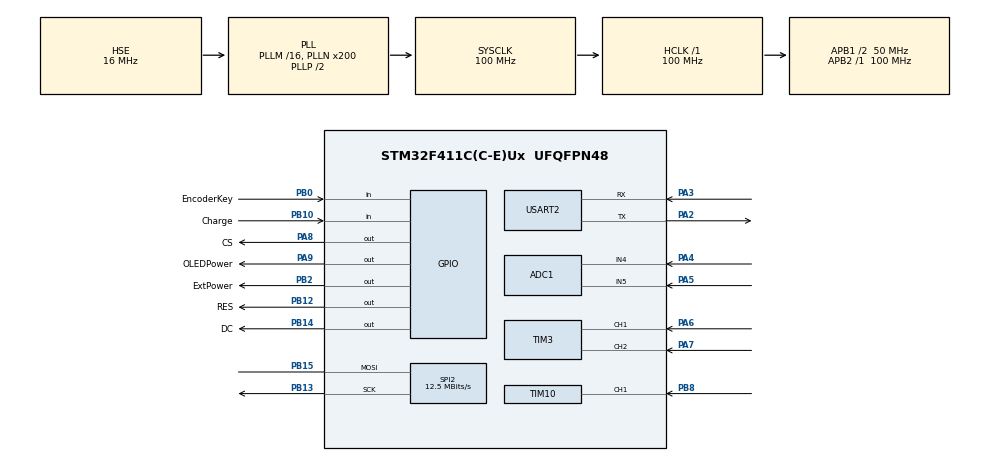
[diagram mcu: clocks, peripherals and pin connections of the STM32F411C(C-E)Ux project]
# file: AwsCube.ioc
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ADC1.Channel-0\#ChannelRegularConversion=ADC_CHANNEL_4
ADC1.NbrOfConversionFlag=1
ADC1.Rank-0\#ChannelRegularConversion=1
ADC1.SamplingTime-0\#ChannelRegularConversion=ADC_SAMPLETIME_3CYCLES
ADC1.master=1
Dma.Request0=SPI2_TX
Dma.Request1=USART2_RX
Dma.SPI2_TX.0.Direction=DMA_MEMORY_TO_PERIPH
Dma.SPI2_TX.0.FIFOMode=DMA_FIFOMODE_DISABLE
Dma.SPI2_TX.0.Instance=DMA1_Stream4
Dma.SPI2_TX.0.MemDataAlignment=DMA_MDATAALIGN_BYTE
Dma.SPI2_TX.0.MemInc=DMA_MINC_ENABLE
Dma.SPI2_TX.0.Mode=DMA_NORMAL
Dma.SPI2_TX.0.PeriphDataAlignment=DMA_PDATAALIGN_BYTE
Dma.SPI2_TX.0.PeriphInc=DMA_PINC_DISABLE
Dma.SPI2_TX.0.Priority=DMA_PRIORITY_LOW
Dma.USART2_RX.1.Direction=DMA_PERIPH_TO_MEMORY
Dma.USART2_RX.1.FIFOMode=DMA_FIFOMODE_DISABLE
Dma.USART2_RX.1.Instance=DMA1_Stream5
Dma.USART2_RX.1.MemDataAlignment=DMA_MDATAALIGN_BYTE
Dma.USART2_RX.1.MemInc=DMA_MINC_ENABLE
Dma.USART2_RX.1.Mode=DMA_NORMAL
Dma.USART2_RX.1.PeriphDataAlignment=DMA_PDATAALIGN_BYTE
Dma.USART2_RX.1.PeriphInc=DMA_PINC_DISABLE
Dma.USART2_RX.1.Priority=DMA_PRIORITY_LOW
FREERTOS.INCLUDE_vTaskDelayUntil=1
FREERTOS.Tasks01=defaultTask,0,128,StartDefaultTask,Default,NULL,Dynamic,NULL,NULL
FREERTOS.configENABLE_FPU=0
Mcu.Family=STM32F4
Mcu.Name=STM32F411C(C-E)Ux
Mcu.Package=UFQFPN48
NVIC.DMA1_Stream4_IRQn=true\:5\:0\:true\:false\:true\:false\:false\:true
NVIC.DMA1_Stream5_IRQn=true\:5\:0\:false\:false\:true\:true\:false\:true
NVIC.PriorityGroup=NVIC_PRIORITYGROUP_4
NVIC.RTC_Alarm_IRQn=true\:8\:0\:true\:false\:true\:true\:true\:true
NVIC.SPI2_IRQn=true\:6\:0\:true\:false\:true\:false\:true\:true
NVIC.TIM1_TRG_COM_TIM11_IRQn=true\:0\:0\:false\:false\:true\:false\:false\:true
NVIC.TIM1_UP_TIM10_IRQn=true\:5\:0\:false\:false\:true\:true\:true\:true
NVIC.TIM3_IRQn=true\:7\:0\:true\:false\:true\:true\:true\:true
NVIC.TimeBase=TIM1_TRG_COM_TIM11_IRQn
NVIC.TimeBaseIP=TIM11
NVIC.USART2_IRQn=true\:7\:0\:true\:false\:true\:true\:true\:true
PA13.Mode=Serial_Wire
PA13.Signal=SYS_JTMS-SWDIO
PA14.Mode=Serial_Wire
PA14.Signal=SYS_JTCK-SWCLK
PA2.Mode=Asynchronous
PA2.Signal=USART2_TX
PA3.Mode=Asynchronous
PA3.Signal=USART2_RX
PA4.Signal=ADCx_IN4
PA5.Signal=ADCx_IN5
PA6.GPIO_PuPd=GPIO_PULLUP
PA6.Signal=S_TIM3_CH1
PA7.GPIO_PuPd=GPIO_PULLUP
PA7.Signal=S_TIM3_CH2
PA8.GPIO_Label=CS
PA8.GPIO_PuPd=GPIO_PULLDOWN
PA8.GPIO_Speed=GPIO_SPEED_FREQ_HIGH
PA8.Signal=GPIO_Output
PA9.GPIO_Label=OLEDPower
PA9.PinState=GPIO_PIN_SET
PA9.Signal=GPIO_Output
PB0.GPIO_Label=EncoderKey
PB0.GPIO_PuPd=GPIO_PULLUP
PB0.Signal=GPIO_Input
PB10.GPIO_Label=Charge
PB10.Signal=GPIO_Input
PB12.GPIO_Label=RES
PB12.GPIO_PuPd=GPIO_PULLDOWN
PB12.GPIO_Speed=GPIO_SPEED_FREQ_HIGH
PB12.Signal=GPIO_Output
PB13.Mode=Simplex_Bidirectional_Master
PB13.Signal=SPI2_SCK
PB14.GPIO_Label=DC
PB14.GPIO_PuPd=GPIO_PULLDOWN
PB14.GPIO_Speed=GPIO_SPEED_FREQ_HIGH
PB14.Signal=GPIO_Output
PB15.Mode=Simplex_Bidirectional_Master
PB15.Signal=SPI2_MOSI
PB2.GPIO_Label=ExtPower
PB2.PinState=GPIO_PIN_SET
PB2.Signal=GPIO_Output
PB8.Signal=S_TIM10_CH1
PC14-OSC32_IN.Mode=LSE-External-Oscillator
PC14-OSC32_IN.Signal=RCC_OSC32_IN
PC15-OSC32_OUT.Mode=LSE-External-Oscillator
PC15-OSC32_OUT.Signal=RCC_OSC32_OUT
PH0\ -\ OSC_IN.Mode=HSE-External-Oscillator
PH0\ -\ OSC_IN.Signal=RCC_OSC_IN
PH1\ -\ OSC_OUT.Mode=HSE-External-Oscillator
PH1\ -\ OSC_OUT.Signal=RCC_OSC_OUT
ProjectManager.HeapSize=0x800
ProjectManager.StackSize=0x800
ProjectManager.TargetToolchain=Makefile
RCC.48MHZClocksFreq_Value=50000000
RCC.AHBFreq_Value=100000000
RCC.APB1CLKDivider=RCC_HCLK_DIV2
RCC.APB1Freq_Value=50000000
RCC.APB1TimFreq_Value=100000000
RCC.APB2Freq_Value=100000000
RCC.APB2TimFreq_Value=100000000
RCC.CortexFreq_Value=100000000
RCC.HCLKFreq_Value=100000000
RCC.HSE_VALUE=16000000
RCC.HSI_VALUE=16000000
RCC.PLLN=200
RCC.PLLSourceVirtual=RCC_PLLSOURCE_HSE
RCC.RCC_RTC_Clock_Source=RCC_RTCCLKSOURCE_LSE
RCC.RCC_RTC_Clock_SourceVirtual=RCC_RTCCLKSOURCE_LSE
RCC.SYSCLKFreq_VALUE=100000000
RCC.SYSCLKSource=RCC_SYSCLKSOURCE_PLLCLK
RCC.VCOOutputFreq_Value=200000000
RTC.Alarm=RTC_ALARM_A
RTC.AlarmMaskDateWeekDay=RTC_ALARMMASK_DATEWEEKDAY
RTC.AlarmMaskHours=RTC_ALARMMASK_HOURS
RTC.AlarmMaskMinutes=RTC_ALARMMASK_MINUTES
RTC.AlarmSubSecondMask=RTC_ALARMSUBSECONDMASK_NONE
RTC.Date=17
RTC.Hours=2
RTC.Month=RTC_MONTH_FEBRUARY
RTC.WeekDay=RTC_WEEKDAY_WEDNESDAY
RTC.Year=21
SH.ADCx_IN4.0=ADC1_IN4,IN4
SH.ADCx_IN5.0=ADC1_IN5,IN5
SH.S_TIM10_CH1.0=TIM10_CH1,Input_Capture1_from_TI1
SH.S_TIM3_CH1.0=TIM3_CH1,Encoder_Interface
SH.S_TIM3_CH2.0=TIM3_CH2,Encoder_Interface
SPI2.BaudRatePrescaler=SPI_BAUDRATEPRESCALER_4
SPI2.CLKPhase=SPI_PHASE_2EDGE
SPI2.CLKPolarity=SPI_POLARITY_HIGH
SPI2.CalculateBaudRate=12.5 MBits/s
SPI2.Direction=SPI_DIRECTION_1LINE
SPI2.Mode=SPI_MODE_MASTER
SPI2.VirtualType=VM_MASTER
TIM10.AutoReloadPreload=TIM_AUTORELOAD_PRELOAD_DISABLE
TIM10.Channel=TIM_CHANNEL_1
TIM10.ICPolarity_CH1=TIM_INPUTCHANNELPOLARITY_FALLING
TIM10.Prescaler=95
TIM3.EncoderMode=TIM_ENCODERMODE_TI2
TIM3.IC1Filter=8
TIM3.IC1Polarity=TIM_ICPOLARITY_FALLING
TIM3.IC1Prescaler=TIM_ICPSC_DIV2
TIM3.IC2Filter=8
TIM3.IC2Polarity=TIM_ICPOLARITY_FALLING
TIM3.IC2Prescaler=TIM_ICPSC_DIV2
USART2.VirtualMode=VM_ASYNC
VP_FREERTOS_VS_CMSIS_V1.Mode=CMSIS_V1
VP_RTC_VS_RTC_Activate.Mode=RTC_Enabled
VP_RTC_VS_RTC_Alarm_A_Intern.Mode=Alarm A
VP_RTC_VS_RTC_Calendar.Mode=RTC_Calendar
VP_SYS_VS_tim11.Mode=TIM11
VP_TIM10_VS_ClockSourceINT.Mode=Enable_Timer
VP_TIM1_VS_ClockSourceINT.Mode=Internal
VP_TIM9_VS_ClockSourceINT.Mode=Internal
board=custom

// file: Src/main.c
/* USER CODE BEGIN Header */
/**
  ******************************************************************************
  * @file           : main.c
  * @brief          : Main program body
  ******************************************************************************
  * @attention
  *
  * <h2><center>&copy; Copyright (c) 2021 STMicroelectronics.
  * All rights reserved.</center></h2>
  *
  * This software component is licensed by ST under Ultimate Liberty license
  * SLA0044, the "License"; You may not use this file except in compliance with
  * the License. You may obtain a copy of the License at:
  *                             www.st.com/SLA0044
  *
  ******************************************************************************
  */
/* USER CODE END Header */
#include "main.h"
#include "cmsis_os.h"
#include "adc.h"
#include "dma.h"
#include "rtc.h"
#include "spi.h"
#include "tim.h"
#include "usart.h"
#include "gpio.h"

/* USER CODE BEGIN Includes */
#include "lvgl.h"
/* USER CODE END Includes */

void SystemClock_Config(void);
void MX_FREERTOS_Init(void);

int main(void)
{

  /* MCU Configuration--------------------------------------------------------*/

  /* Reset of all peripherals, Initializes the Flash interface and the Systick. */
  HAL_Init();

  /* Configure the system clock */
  SystemClock_Config();

  /* Initialize all configured peripherals */
  MX_GPIO_Init();
  MX_DMA_Init();
  MX_TIM1_Init();
  MX_TIM9_Init();
  MX_TIM10_Init();
  MX_SPI2_Init();
  MX_RTC_Init();
  MX_ADC1_Init();
  MX_TIM3_Init();
  MX_USART2_UART_Init();
  /* USER CODE BEGIN 2 */
  	// uint8_t tdata[10];
    // HAL_UART_Transmit(&huart2,"1234",4,100);
// HAL_UART_Receive_IT(&huart2,tdata,10);
  /* USER CODE END 2 */

  /* Call init function for freertos objects (in freertos.c) */
  MX_FREERTOS_Init();
  /* Start scheduler */
  osKernelStart();

  /* We should never get here as control is now taken by the scheduler */
  /* Infinite loop */
  while (1)
  {

  }
}

void SystemClock_Config(void)
{
  RCC_OscInitTypeDef RCC_OscInitStruct = {0};
  RCC_ClkInitTypeDef RCC_ClkInitStruct = {0};
  RCC_PeriphCLKInitTypeDef PeriphClkInitStruct = {0};

  /** Configure the main internal regulator output voltage
  */
  __HAL_RCC_PWR_CLK_ENABLE();
  __HAL_PWR_VOLTAGESCALING_CONFIG(PWR_REGULATOR_VOLTAGE_SCALE1);
  /** Initializes the RCC Oscillators according to the specified parameters
  * in the RCC_OscInitTypeDef structure.
  */
  RCC_OscInitStruct.OscillatorType = RCC_OSCILLATORTYPE_HSE|RCC_OSCILLATORTYPE_LSE;
  RCC_OscInitStruct.HSEState = RCC_HSE_ON;
  RCC_OscInitStruct.LSEState = RCC_LSE_ON;
  RCC_OscInitStruct.PLL.PLLState = RCC_PLL_ON;
  RCC_OscInitStruct.PLL.PLLSource = RCC_PLLSOURCE_HSE;
  RCC_OscInitStruct.PLL.PLLM = 16;
  RCC_OscInitStruct.PLL.PLLN = 200;
  RCC_OscInitStruct.PLL.PLLP = RCC_PLLP_DIV2;
  RCC_OscInitStruct.PLL.PLLQ = 4;
  if (HAL_RCC_OscConfig(&RCC_OscInitStruct) != HAL_OK)
  {
    Error_Handler();
  }
  /** Initializes the CPU, AHB and APB buses clocks
  */
  RCC_ClkInitStruct.ClockType = RCC_CLOCKTYPE_HCLK|RCC_CLOCKTYPE_SYSCLK
                              |RCC_CLOCKTYPE_PCLK1|RCC_CLOCKTYPE_PCLK2;
  RCC_ClkInitStruct.SYSCLKSource = RCC_SYSCLKSOURCE_PLLCLK;
  RCC_ClkInitStruct.AHBCLKDivider = RCC_SYSCLK_DIV1;
  RCC_ClkInitStruct.APB1CLKDivider = RCC_HCLK_DIV2;
  RCC_ClkInitStruct.APB2CLKDivider = RCC_HCLK_DIV1;

  if (HAL_RCC_ClockConfig(&RCC_ClkInitStruct, FLASH_LATENCY_3) != HAL_OK)
  {
    Error_Handler();
  }
  PeriphClkInitStruct.PeriphClockSelection = RCC_PERIPHCLK_RTC;
  PeriphClkInitStruct.RTCClockSelection = RCC_RTCCLKSOURCE_LSE;
  if (HAL_RCCEx_PeriphCLKConfig(&PeriphClkInitStruct) != HAL_OK)
  {
    Error_Handler();
  }
}

/* USER CODE BEGIN 4 */
void TIM10_PeriodElapsedHandle(void);
void UART2_Receive_CB(void);
void RTC_Alarm_CB(void);
void HAL_UART_RxCpltCallback(UART_HandleTypeDef *huart)
{
	if(huart->Instance == USART2)
	{
		UART2_Receive_CB();
	}
}

void HAL_RTC_AlarmAEventCallback(RTC_HandleTypeDef *hrtc)
{
  if(hrtc->Instance == RTC)
  {
    asm("NOP");
    RTC_Alarm_CB();
  }

}

/* USER CODE END 4 */

 /**
  * @brief  Period elapsed callback in non blocking mode
  * @note   This function is called  when TIM11 interrupt took place, inside
  * HAL_TIM_IRQHandler(). It makes a direct call to HAL_IncTick() to increment
  * a global variable "uwTick" used as application time base.
  * @param  htim : TIM handle
  * @retval None
  */
void HAL_TIM_PeriodElapsedCallback(TIM_HandleTypeDef *htim)
{
  if (htim->Instance == TIM11) {
    HAL_IncTick();
    lv_tick_inc(1);
  }
  /* USER CODE BEGIN Callback 1 */
  if(htim->Instance == TIM10) {
 		TIM10_PeriodElapsedHandle();
  }
  /* USER CODE END Callback 1 */
}

void Error_Handler(void)
{
}

/************************ (C) COPYRIGHT STMicroelectronics *****END OF FILE****/
